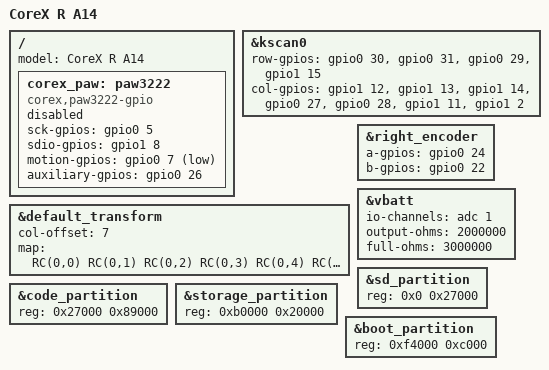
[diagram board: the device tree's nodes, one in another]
/* SPDX-License-Identifier: MIT
 * CoreX R A14 pins: CoreX-RMK/source/corex-rmk-pair/right/keyboard-raytac.toml
 * and src/main.rs. Do not flash this board definition to stock Cornix.
 */
/dts-v1/;
#include "../cornix/cornix.dtsi"

/ { model = "CoreX R A14"; };
&kscan0 {
    row-gpios = <&gpio0 30 (GPIO_ACTIVE_HIGH | GPIO_PULL_DOWN)>,
                <&gpio0 31 (GPIO_ACTIVE_HIGH | GPIO_PULL_DOWN)>,
                <&gpio0 29 (GPIO_ACTIVE_HIGH | GPIO_PULL_DOWN)>,
                <&gpio1 15 (GPIO_ACTIVE_HIGH | GPIO_PULL_DOWN)>;
    col-gpios = <&gpio1 12 GPIO_ACTIVE_HIGH>, <&gpio1 13 GPIO_ACTIVE_HIGH>,
                <&gpio1 14 GPIO_ACTIVE_HIGH>, <&gpio0 27 GPIO_ACTIVE_HIGH>,
                <&gpio0 28 GPIO_ACTIVE_HIGH>, <&gpio1 11 GPIO_ACTIVE_HIGH>,
                <&gpio1 2 GPIO_ACTIVE_HIGH>;
};
&default_transform {
    col-offset = <7>;
    /* Same logical positions as Cornix; encoder switch is A14 row 2/col 6. */
    map = <
        RC(0,0) RC(0,1) RC(0,2) RC(0,3) RC(0,4) RC(0,5) RC(0,12) RC(0,11) RC(0,10) RC(0,9) RC(0,8) RC(0,7)
        RC(1,0) RC(1,1) RC(1,2) RC(1,3) RC(1,4) RC(1,5) RC(1,12) RC(1,11) RC(1,10) RC(1,9) RC(1,8) RC(1,7)
        RC(2,0) RC(2,1) RC(2,2) RC(2,3) RC(2,4) RC(2,5) RC(2,6) RC(2,13) RC(2,12) RC(2,11) RC(2,10) RC(2,9) RC(2,8) RC(2,7)
        RC(3,0) RC(3,1) RC(3,2) RC(3,3) RC(3,4) RC(3,5) RC(3,12) RC(3,11) RC(3,10) RC(3,9) RC(3,8) RC(3,7)
    >;
};
&right_encoder {
    status = "okay";
    a-gpios = <&gpio0 24 (GPIO_ACTIVE_HIGH | GPIO_PULL_UP)>;
    b-gpios = <&gpio0 22 (GPIO_ACTIVE_HIGH | GPIO_PULL_UP)>;
};
&vbatt {
    io-channels = <&adc 1>; /* P0.03 / AIN1 */
    output-ohms = <2000000>;
    full-ohms = <3000000>;
};
/* Retain the installed SoftDevice and bootloader. No nrf52840-nosd snippet. */
&sd_partition { reg = <0x0 0x27000>; };
&code_partition { reg = <0x27000 0x89000>; };
&storage_partition { reg = <0xb0000 0x20000>; };
&boot_partition { reg = <0xf4000 0xc000>; };

/ {
    corex_paw: paw3222 {
        compatible = "corex,paw3222-gpio";
        status = "disabled";
        /* J4 is the default; J3 shield replaces all four pins. */
        sck-gpios = <&gpio0 5 GPIO_ACTIVE_HIGH>;
        sdio-gpios = <&gpio1 8 GPIO_ACTIVE_HIGH>;
        motion-gpios = <&gpio0 7 (GPIO_ACTIVE_LOW | GPIO_PULL_UP)>;
        auxiliary-gpios = <&gpio0 26 GPIO_ACTIVE_HIGH>;
    };
};
